AUTOSAR XML (schema 4-2-1)
package /COM/VECTOR/CFG/WORKFLOW/SYSDESC/SYNC
  system SYSTEM
    system mapping MAPPINGS
      data-mappings:
        data-element=COMPOSITIONTYPE.PpLightStateRear.DeLightState, system-signal=sig_RearInteriorLight
        data-element=COMPOSITIONTYPE.PpDoorStateRearRight.DeDoorState, system-signal=sig_State_RearRightDoor
        data-element=COMPOSITIONTYPE.PpDoorStateRearLeft.DeDoorState, system-signal=sig_State_RearLeftDoor
    root-software-compositions:
      root sw composition prototype COMPOSITIONTYPE: flat-map=FLATMAP, software-composition=COMPOSITIONTYPE
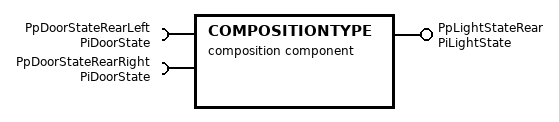
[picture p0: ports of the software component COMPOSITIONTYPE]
  composition sw component type COMPOSITIONTYPE
    provide port PpLightStateRear: nonqueued-sender-com-spec{data-element=DeLightState, init-value=constant-reference=CLightOff}, provided-interface=PiLightState
    require port PpDoorStateRearLeft: nonqueued-receiver-com-spec{data-element=DeDoorState, filter=data-filter-type=ALWAYS, init-value=constant-reference=CDoorClosed}, required-interface=PiDoorState
    require port PpDoorStateRearRight: nonqueued-receiver-com-spec{data-element=DeDoorState, filter=data-filter-type=ALWAYS, init-value=constant-reference=CDoorClosed}, required-interface=PiDoorState
    12 x component:
      BswM: type=BswM
      Dem: type=Dem
      Det: type=Det
      EcuM: type=EcuM
      NvM: type=NvM
      CpSaInteriorLightFront: type=CtSaInteriorLight
      CpSaDoorFrontRight: type=CtSaDoor
      CpSaDoorFrontLeft: type=CtSaDoor
      CpSaDisplay: type=CtSaDisplay
      CpApMySwc: type=CtApMySwc
      CpCddIoHwAb: type=CtCddIoHwAb
      ComM: type=ComM
    connect BswM.Switch_ESH_ModeSwitch -> BswM.Notification_ESH_ModeNotification
    connect CpApMySwc.PpDisplayState -> CpSaDisplay.PpDisplayState
    connect CpApMySwc.PpLightStateFront -> CpSaInteriorLightFront.PpLightState
    connect CpSaDisplay.PpLocalIgnitionState -> CpApMySwc.PpLocalIgnitionState
    connect CpSaDoorFrontLeft.PpDoorState -> CpApMySwc.PpDoorStateFrontLeft
    connect CpSaDoorFrontRight.PpDoorState -> CpApMySwc.PpDoorStateFrontRight
    delegate CpApMySwc.PpLightStateRear <-> outer port PpLightStateRear
    delegate CpApMySwc.PpDoorStateRearRight <-> outer port PpDoorStateRearRight
    delegate CpApMySwc.PpDoorStateRearLeft <-> outer port PpDoorStateRearLeft
    connect CpCddIoHwAb.PpDisplayState -> CpSaDisplay.PpDisplayStateIoHwAb
    connect CpCddIoHwAb.PpLocalClamp15 -> CpSaDisplay.PplocalIgnitionStateIoHwAb
    connect CpCddIoHwAb.PpDoorFrontLeft -> CpSaDoorFrontLeft.PpDoorIoHwAb
    connect CpCddIoHwAb.PpDoorFrontRight -> CpSaDoorFrontRight.PpDoorIoHwAb
    connect CpCddIoHwAb.PpInteriorLightFrontDEFECT -> CpSaInteriorLightFront.PpInteriorLightDefect
    connect CpCddIoHwAb.PpInteriorLightFront -> CpSaInteriorLightFront.PpInteriorLightIoHwAb
    connect CpApMySwc.PpBswMRequestShutdown -> BswM.Notification_SWCModeSwitch_BswM_MdgBswMRequestShutdown
    connect NvM.PS_CpApMySwcSnNvMPimLightOnOffCounter -> CpApMySwc.PpNvMLightOnOffCtApMySwc
    connect NvM.PS_CpApMySwcSnNvMPimOdometer -> CpApMySwc.PpNvMOdometerCtApMySwc
    connect NvM.PS_NvMConfigBlock -> CpApMySwc.PpNvMConfigBlockCtApMySwc
    connect CpApMySwc.PpNvMNotifyJobFinishedOdometerCtApMySwc -> NvM.NvM_RpNotifyJobEnd_CpApMySwcSnNvMPimOdometer
    connect ComM.UM_USR_CHNL_CAN00 -> CpApMySwc.PpComMCurrentModeCtApMySwc
    connect ComM.UR_USR_CHNL_CAN00 -> CpApMySwc.PpComMUserRequestCtApMySwc
  end to end protection set E2EPROTECTIONSET
  port interface mapping set PORTINTERFACEMAPPINGSET
